# BCM2711_SPI register map
File version: 1
BCM2711 SPI master (SPI0, SPI3 to SPI6)
Registers are read-write, no defined reset value unless marked. A register's access mark holds for its fields unless they carry their own. Offsets are from the block's base; lines under a group give offsets from that group; [hi:lo] are bit positions; {n}, {i} and the like mark numbered series; 'fields as' and 'values as' point back to an identical list; <NAME> marks a mode.

## Memory map
0x00000000 BCM2711_SPI size 0x18

## BCM2711_SPI
Base 0x00000000
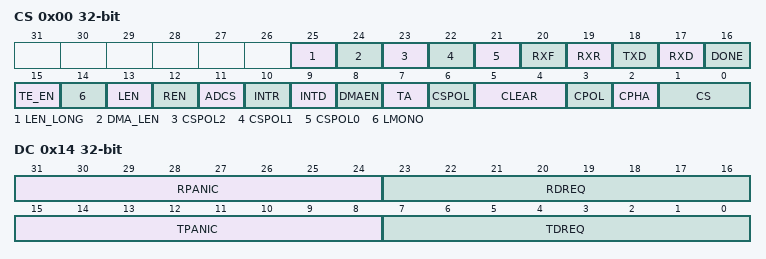
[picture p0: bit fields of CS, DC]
0x00 CS — Control and status (Table 160); CLEAR is one-shot and reads back 0, the FIFO and transfer flags are read-only
  [25] LEN_LONG — With DMA_LEN, 1 makes a FIFO write a 32-bit word in LoSSI mode, 0 a byte
  [24] DMA_LEN — 1 enables DMA mode in LoSSI mode
  [23] CSPOL2 — Chip select 2 active: 0 low, 1 high
  [22] CSPOL1 — Chip select 1 active: 0 low, 1 high
  [21] CSPOL0 — Chip select 0 active: 0 low, 1 high
  [20] RXF ro — 1 while the RX FIFO is full; the transfer stalls until it is read
  [19] RXR ro — 1 while the RX FIFO is three quarters full or more and TA is 1
  [18] TXD ro — 1 while the TX FIFO has room for a byte
  [17] RXD ro — 1 while the RX FIFO holds a byte
  [16] DONE ro — 1 once the transfer completes; cleared by writing more data to the TX FIFO or by clearing TA
  [15] TE_EN — Unused (Table 160)
  [14] LMONO — Unused (Table 160)
  [13] LEN — 1 makes the controller a LoSSI master, 0 an SPI master
  [12] REN — Read enable in bidirectional mode: 1 the next transfer reads; resets to 1
  [11] ADCS — 1 deasserts the chip select at the end of a DMA transfer
  [10] INTR — Interrupt while RXR is 1
  [9] INTD — Interrupt while DONE is 1
  [8] DMAEN — 1 enables DMA requests
  [7] TA — 1 while a transfer is active, the chip select asserted by CS and CSPOL; 0 deasserts every chip select and clears RXR and DONE
  [6] CSPOL — Chip select lines active: 0 low, 1 high
  [5:4] CLEAR — Bit 0 clears the TX FIFO, bit 1 the RX FIFO, one-shot, read back 0; set with TA, the FIFOs are cleared before the transfer starts
  [3] CPOL — The rest state of SCLK: 0 low, 1 high
  [2] CPHA — 0 the first SCLK transition at the middle of a data bit, 1 at its beginning
  [1:0] CS — The chip select a transfer asserts
    0=CE0; 1=CE1; 2=CE2
0x04 FIFO read-modifies — TX and RX FIFOs (Table 161): with TA set and DMAEN clear, a write queues a byte to send and a read takes the next byte received; with DMAEN set and TA clear, the first write sets DLEN and CS's low byte
  [31:0] DATA
0x08 CLK — Clock divider (Table 162): SCLK is the core clock divided by CDIV, odd values rounded down; 0 divides by 65536; unverified the fastest rate, which Table 162 leaves blank ("is of the APB clock")
  [15:0] CDIV
0x0C DLEN — Data length (Table 163): the bytes a DMA transfer moves; meaningful only with DMAEN set
  [15:0] LEN
0x10 LTOH — LoSSI output hold (Table 164): the hold delay in APB clocks, 0 meaning 1
  [3:0] TOH
0x14 DC — DMA request and panic thresholds (Table 165), in FIFO levels
  [31:24] RPANIC — RX panic while the RX FIFO level is above this
  [23:16] RDREQ — RX DREQ while the RX FIFO level is above this, or the transfer has finished with the RX FIFO not empty
  [15:8] TPANIC — TX panic while the TX FIFO level is at most this
  [7:0] TDREQ — TX DREQ while the TX FIFO level is at most this

## Notices in the file
Copyright (c) 2026, Stanislav Sedov <stas@deglitch.com>
SPDX-License-Identifier: BSD-2-Clause
